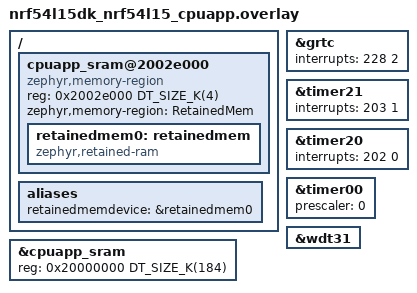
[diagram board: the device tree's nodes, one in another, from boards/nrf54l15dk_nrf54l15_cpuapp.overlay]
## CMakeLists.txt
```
# SPDX-License-Identifier: Apache-2.0

cmake_minimum_required(VERSION 3.20.0)

find_package(Zephyr REQUIRED HINTS $ENV{ZEPHYR_BASE})
project(nrf_grtc_timer)

target_sources(app PRIVATE 
    src/main.c
    src/utc_time.c
    src/retained.c
)
```

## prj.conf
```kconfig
# Disable ZTEST framework
# CONFIG_ZTEST is not set

# GRTC Timer support
CONFIG_NRF_GRTC_TIMER=y
CONFIG_COUNTER=y

# Logging
CONFIG_LOG=y
CONFIG_LOG_PRINTK=y

# System reboot support
CONFIG_REBOOT=y

# Retained memory support for software reset persistence
CONFIG_RETAINED_MEM=y
CONFIG_CRC=y

CONFIG_LOG_MODE_IMMEDIATE=y
CONFIG_WATCHDOG=y
CONFIG_WDT_DISABLE_AT_BOOT=n
```

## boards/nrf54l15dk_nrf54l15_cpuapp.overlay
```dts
/* SPDX-License-Identifier: Apache-2.0 */

&grtc {
	interrupts = <228 2>;
};

test_timer: &timer21 {
	status = "okay";
	interrupts = <203 1>;
};

&timer20 {
	status = "okay";
	interrupts = <202 0>;
};

&timer00 {
	status = "okay";
	prescaler = <0>;
};

&wdt31 {
	status = "okay";
};

/ {
	cpuapp_sram@2002e000 {
		compatible = "zephyr,memory-region", "mmio-sram";
		reg = <0x2002e000 DT_SIZE_K(4)>;
		zephyr,memory-region = "RetainedMem";
		status = "okay";

		retainedmem0: retainedmem {
			compatible = "zephyr,retained-ram";
			status = "okay";
		};
	};

	aliases {
		retainedmemdevice = &retainedmem0;
	};
};

&cpuapp_sram {
	/* Shrink SRAM size to avoid overlap with retained memory region */
	reg = <0x20000000 DT_SIZE_K(184)>;
	ranges = <0x0 0x20000000 0x2e000>;
};
```

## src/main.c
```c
/*
 * Copyright (c) 2024 Nordic Semiconductor ASA
 *
 * SPDX-License-Identifier: Apache-2.0
 * 
 * GRTC RAM Retention Demo
 * Demonstrates that nRF54L15 GRTC automatically persists through software reset
 */

#include <zephyr/kernel.h>
#include <zephyr/logging/log.h>
#include <zephyr/sys/reboot.h>
#include <zephyr/drivers/timer/nrf_grtc_timer.h>
#include "retained.h"
#include <zephyr/drivers/watchdog.h>
#include <zephyr/device.h>
#include <stdbool.h>

LOG_MODULE_REGISTER(utc_time_demo, LOG_LEVEL_INF);

// #define WDT_TEST 0

#define MAX_REBOOTS 3  // Maximum number of automatic resets
#define WDT_FEED_TRIES 5
#define WDT_ALLOW_CALLBACK 0

#ifndef WDT_MAX_WINDOW
#define WDT_MAX_WINDOW  1000U
#endif

#ifndef WDT_MIN_WINDOW
#define WDT_MIN_WINDOW  0U
#endif

#ifndef WDG_FEED_INTERVAL
#define WDG_FEED_INTERVAL 50U
#endif

#ifndef WDT_OPT
#define WDT_OPT WDT_OPT_PAUSE_HALTED_BY_DBG
#endif
int wdt_channel_id;
const struct device *const wdt = DEVICE_DT_GET(DT_ALIAS(watchdog0));

int watch_dog(void)
{
	int err;


	LOG_INF("Watchdog sample application\n");

	if (!device_is_ready(wdt)) {
		LOG_INF("%s: device not ready.\n", wdt->name);
		return 0;
	}

	struct wdt_timeout_cfg wdt_config = {
		/* Reset SoC when watchdog timer expires. */
		.flags = WDT_FLAG_RESET_SOC,

		/* Expire watchdog after max window */
		.window.min = WDT_MIN_WINDOW,
		.window.max = WDT_MAX_WINDOW,
	};

#if WDT_ALLOW_CALLBACK
	/* Set up watchdog callback. */
	wdt_config.callback = wdt_callback;

	LOG_INF("Attempting to test pre-reset callback\n");
#else /* WDT_ALLOW_CALLBACK */
	LOG_INF("Callback in RESET_SOC disabled for this platform\n");
#endif /* WDT_ALLOW_CALLBACK */

	wdt_channel_id = wdt_install_timeout(wdt, &wdt_config);
	if (wdt_channel_id == -ENOTSUP) {
		/* IWDG driver for STM32 doesn't support callback */
		LOG_INF("Callback support rejected, continuing anyway\n");
		wdt_config.callback = NULL;
		wdt_channel_id = wdt_install_timeout(wdt, &wdt_config);
	}
	if (wdt_channel_id < 0) {
		LOG_INF("Watchdog install error\n");
		return 0;
	}

	err = wdt_setup(wdt, WDT_OPT);
	if (err < 0) {
		LOG_INF("Watchdog setup error\n");
		return 0;
	}

#if WDT_MIN_WINDOW != 0
	/* Wait opening window. */
	k_msleep(WDT_MIN_WINDOW);
#endif

	return 0;
}

// Work queue for triggering software reset
static void reboot_work_handler(struct k_work *work);
static K_WORK_DELAYABLE_DEFINE(reboot_work, reboot_work_handler);

static void reboot_work_handler(struct k_work *work)
{
	LOG_WRN("\n========================================");
	LOG_WRN("=== INITIATING SOFTWARE RESET #%u ===", retained.boots + 1);
	LOG_WRN("========================================");
	
	// Record GRTC state before reset
	uint64_t grtc_before = z_nrf_grtc_timer_read();
	
	LOG_WRN("BEFORE RESET:");
	LOG_WRN("  GRTC counter: %llu us (%.3f sec)", grtc_before, (double)grtc_before / 1000000.0);
	
	LOG_WRN("\n>>> Performing software reset NOW...");
	LOG_WRN(">>> GRTC should continue counting from %llu us", grtc_before);
	
	// Update retained memory - increment boots counter
	retained.boots++;
	retained_update();
	LOG_WRN(">>> Saved retained data to RAM:");
	LOG_WRN("    boots=%u, off_count=%u, uptime_sum=%llu", 
	        retained.boots, retained.off_count, retained.uptime_sum);
	
	k_msleep(100); // Allow time for log output
	
	// Execute software reset
	sys_reboot(SYS_REBOOT_COLD);	
}

int main(void)
{
	LOG_INF("GRTC Retention Test Starting...");
	LOG_INF("========================================");
	
	// Initialize retained memory
	bool retained_ok = retained_validate();
	LOG_INF("Retained RAM: %s", retained_ok ? "VALID" : "INVALID (first boot)");
	if (retained_ok) {
		LOG_INF("=== Retained Data ===");
		LOG_INF("  boots:         %u", retained.boots);
		LOG_INF("  off_count:     %u", retained.off_count);
		LOG_INF("  uptime_latest: %llu ticks", retained.uptime_latest);
		LOG_INF("  uptime_sum:    %llu ticks (%.3f sec)", 
		        retained.uptime_sum,
		        (double)retained.uptime_sum * 1000.0 / CONFIG_SYS_CLOCK_TICKS_PER_SEC / 1000.0);
		LOG_INF("  crc:           0x%08x", retained.crc);
	}
	
	// Check GRTC current state (post-reset verification)
	uint64_t grtc_raw = z_nrf_grtc_timer_read();
	
	LOG_INF("GRTC raw counter: %llu us (%.3f seconds)", grtc_raw, (double)grtc_raw / 1000000.0);
	LOG_WRN("Current boot count: %u", retained.boots);

#ifndef WDT_TEST	
	// Check if recovering from software reset
	if (grtc_raw > 1000000ULL) {
		LOG_WRN("========================================");
		LOG_WRN(">>> SUCCESS: GRTC RETENTION WORKING! <<<");
		LOG_WRN("========================================");
		LOG_WRN("Counter value: %llu us = %.3f seconds", grtc_raw, (double)grtc_raw / 1000000.0);
		LOG_WRN("This proves GRTC has been running continuously through software reset!");
		
		// Increment off_count (reset counter)
		retained.off_count++;
	} else {
		LOG_INF(">>> GRTC appears to be freshly started (first boot or hard reset)");
		LOG_INF(">>> Counter < 1 second indicates cold boot");
	}
	
	LOG_INF("Boot count: %u (max reboots: %u)", retained.boots, MAX_REBOOTS);
	LOG_INF("========================================");
	
	// Automatically trigger software reset (to verify retention)
	if (retained.boots < MAX_REBOOTS) {
		LOG_WRN("\n=== AUTO REBOOT TEST ===");
		LOG_WRN("Will trigger software reset in 10 seconds...");
		LOG_WRN("This is to verify GRTC retention across resets");
		LOG_WRN("Current boot count: %u / %u", retained.boots, MAX_REBOOTS);
		
		// Delay 10 seconds before triggering reset
		k_work_schedule(&reboot_work, K_SECONDS(10));
		
		// Countdown display
		for (int i = 10; i > 0; i--) {
			LOG_WRN(">>> Software reset in %d seconds...", i);
			k_sleep(K_SECONDS(1));
		}
	} else {
		LOG_INF("\n=== REBOOT TEST COMPLETE ===");
		LOG_INF(">>> Maximum reboot count (%u) reached", MAX_REBOOTS);
		LOG_INF("========================================");
		LOG_INF(">>> GRTC RETENTION VALIDATED! <<<");
		LOG_INF("========================================");
		LOG_INF("The GRTC counter has persisted through %u software resets", MAX_REBOOTS);
		LOG_INF("Current GRTC value: %llu us (%.3f seconds)", 
		        z_nrf_grtc_timer_read(), 
		        (double)z_nrf_grtc_timer_read() / 1000000.0);
	}
#else
	watch_dog();
#endif		
#ifndef WDT_TEST
	// Keep program running, continuously display GRTC counter
	while (1) {

	k_sleep(K_SECONDS(1));				

	/* Waiting for the SoC reset. */
	LOG_INF("Waiting for reset...\n");		
		k_sleep(K_SECONDS(10));
		uint64_t grtc_current = z_nrf_grtc_timer_read();
		
		// Update retained memory to accumulate uptime
		retained_update();
		
		LOG_INF("=== Status ===");
		LOG_INF("GRTC: %llu us (%.3f sec)", 
		        grtc_current,
		        (double)grtc_current / 1000000.0);
		LOG_INF("Retained: boots=%u, off_count=%u, uptime_sum=%llu ticks (%.3f sec)",
		        retained.boots,
		        retained.off_count,
		        retained.uptime_sum,
		        (double)retained.uptime_sum * 1000.0 / CONFIG_SYS_CLOCK_TICKS_PER_SEC / 1000.0);
	}
#else
	/* Feeding watchdog. */

	LOG_INF("Feeding watchdog %d times\n", WDT_FEED_TRIES);

	for (int i = 0; i < WDT_FEED_TRIES; ++i) {
		LOG_INF("Feeding watchdog...\n");
		wdt_feed(wdt, wdt_channel_id);
		k_sleep(K_MSEC(WDG_FEED_INTERVAL));
	}
#endif	
	return 0;
}
```

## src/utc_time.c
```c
/*
 * UTC Time Management using GRTC Timer
 * Copyright (c) 2025
 * 
 * NOTE: On nRF54L15/nRF54H20, GRTC (Global Real-Time Counter) automatically 
 * persists through software reset when CONFIG_NRF_GRTC_TIMER=y is enabled.
 * No manual KEEPRUNNING register configuration is needed.
 */

#include <zephyr/kernel.h>
#include <zephyr/drivers/timer/nrf_grtc_timer.h>
#include <zephyr/logging/log.h>
#include "utc_time.h"

LOG_MODULE_REGISTER(utc_time, LOG_LEVEL_INF);

/* UTC time offset (microseconds) */
static int64_t utc_offset = 0;
static bool calibrated = false;

/**
 * @brief Calibrate UTC time with external time source
 * 
 * @param utc_timestamp_us UTC timestamp in microseconds
 */
void utc_time_calibrate(uint64_t utc_timestamp_us)
{
	uint64_t grtc_time = z_nrf_grtc_timer_read();
	utc_offset = (int64_t)utc_timestamp_us - (int64_t)grtc_time;
	calibrated = true;
	
	LOG_INF("UTC time calibrated");
	LOG_INF("  GRTC time: %llu us", grtc_time);
	LOG_INF("  UTC time:  %llu us", utc_timestamp_us);
	LOG_INF("  Offset:    %lld us", utc_offset);
}

/**
 * @brief Calibrate UTC time with Unix timestamp (seconds since 1970-01-01)
 * 
 * @param unix_timestamp Unix timestamp in seconds
 */
void utc_time_calibrate_unix(uint64_t unix_timestamp)
{
	uint64_t utc_us = unix_timestamp * 1000000ULL;
	utc_time_calibrate(utc_us);
}

/**
 * @brief Check if UTC time is calibrated
 * 
 * @return true if calibrated, false otherwise
 */
bool utc_time_is_calibrated(void)
{
	return calibrated;
}

/**
 * @brief Get current UTC timestamp in microseconds
 * 
 * @return UTC timestamp in microseconds, or raw GRTC if not calibrated
 */
uint64_t utc_time_get_us(void)
{
	uint64_t grtc_time = z_nrf_grtc_timer_read();
	
	if (!calibrated) {
		LOG_WRN("UTC time not calibrated, returning raw GRTC time");
		return grtc_time;
	}
	
	return grtc_time + utc_offset;
}

/**
 * @brief Get current UTC timestamp in milliseconds
 * 
 * @return UTC timestamp in milliseconds
 */
uint64_t utc_time_get_ms(void)
{
	return utc_time_get_us() / 1000ULL;
}

/**
 * @brief Get current UTC timestamp in seconds
 * 
 * @return UTC timestamp in seconds (Unix timestamp)
 */
uint64_t utc_time_get_sec(void)
{
	return utc_time_get_us() / 1000000ULL;
}

/**
 * @brief Get UTC time as struct
 * 
 * @param time Pointer to utc_time_t structure to fill
 */
void utc_time_get(utc_time_t *time)
{
	if (time == NULL) {
		return;
	}
	
	uint64_t us = utc_time_get_us();
	
	time->microseconds = us;
	time->milliseconds = us / 1000ULL;
	time->seconds = us / 1000000ULL;
	time->calibrated = calibrated;
}

/**
 * @brief Print current UTC time
 */
void utc_time_print(void)
{
	utc_time_t time;
	utc_time_get(&time);
	
	if (time.calibrated) {
		LOG_INF("UTC Time: %llu sec (%llu ms, %llu us)", 
		        time.seconds, time.milliseconds, time.microseconds);
	} else {
		LOG_INF("GRTC Time (not calibrated): %llu us", time.microseconds);
	}
}

/**
 * @brief Get time difference in microseconds
 * 
 * @param time1 First timestamp (microseconds)
 * @param time2 Second timestamp (microseconds)
 * @return Time difference in microseconds (time2 - time1)
 */
int64_t utc_time_diff_us(uint64_t time1, uint64_t time2)
{
	return (int64_t)time2 - (int64_t)time1;
}

/**
 * @brief Convert microseconds to human-readable format
 * 
 * @param us Microseconds
 * @param buffer Output buffer
 * @param size Buffer size
 * @return Number of characters written
 */
int utc_time_format_us(uint64_t us, char *buffer, size_t size)
{
	uint64_t sec = us / 1000000ULL;
	uint64_t ms = (us / 1000ULL) % 1000ULL;
	uint64_t remaining_us = us % 1000ULL;
	
	return snprintf(buffer, size, "%llu.%03llu.%03llu s", sec, ms, remaining_us);
}

/**
 * @brief Format current UTC time to human-readable string
 * 
 * @param buffer Output buffer
 * @param size Buffer size
 * @return Number of characters written
 */
int utc_time_format(char *buffer, size_t size)
{
	uint64_t us = utc_time_get_us();
	return utc_time_format_us(us, buffer, size);
}
```

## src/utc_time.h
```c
/*
 * UTC Time Management using GRTC Timer - Header File
 * 
 * NOTE: On nRF54L15/nRF54H20, GRTC automatically persists through 
 * software reset (CONFIG_NRF_GRTC_TIMER=y). No manual retention
 * configuration is needed.
 */

#ifndef UTC_TIME_H
#define UTC_TIME_H

#include <zephyr/types.h>
#include <stdbool.h>

/**
 * @brief UTC time structure
 */
typedef struct {
	uint64_t microseconds;  /**< Time in microseconds */
	uint64_t milliseconds;  /**< Time in milliseconds */
	uint64_t seconds;       /**< Time in seconds (Unix timestamp) */
	bool calibrated;        /**< Whether time is calibrated */
} utc_time_t;

/**
 * @brief Calibrate UTC time with external time source
 * 
 * @param utc_timestamp_us UTC timestamp in microseconds
 */
void utc_time_calibrate(uint64_t utc_timestamp_us);

/**
 * @brief Calibrate UTC time with Unix timestamp (seconds since 1970-01-01)
 * 
 * @param unix_timestamp Unix timestamp in seconds
 */
void utc_time_calibrate_unix(uint64_t unix_timestamp);

/**
 * @brief Check if UTC time is calibrated
 * 
 * @return true if calibrated, false otherwise
 */
bool utc_time_is_calibrated(void);

/**
 * @brief Get current UTC timestamp in microseconds
 * 
 * @return UTC timestamp in microseconds, or raw GRTC if not calibrated
 */
uint64_t utc_time_get_us(void);

/**
 * @brief Get current UTC timestamp in milliseconds
 * 
 * @return UTC timestamp in milliseconds
 */
uint64_t utc_time_get_ms(void);

/**
 * @brief Get current UTC timestamp in seconds
 * 
 * @return UTC timestamp in seconds (Unix timestamp)
 */
uint64_t utc_time_get_sec(void);

/**
 * @brief Get UTC time as struct
 * 
 * @param time Pointer to utc_time_t structure to fill
 */
void utc_time_get(utc_time_t *time);

/**
 * @brief Print current UTC time
 */
void utc_time_print(void);

/**
 * @brief Get time difference in microseconds
 * 
 * @param time1 First timestamp (microseconds)
 * @param time2 Second timestamp (microseconds)
 * @return Time difference in microseconds (time2 - time1)
 */
int64_t utc_time_diff_us(uint64_t time1, uint64_t time2);

/**
 * @brief Convert microseconds to human-readable format
 * 
 * @param us Microseconds
 * @param buffer Output buffer
 * @param size Buffer size
 * @return Number of characters written
 */
int utc_time_format_us(uint64_t us, char *buffer, size_t size);

/**
 * @brief Format current UTC time to human-readable string
 * 
 * @param buffer Output buffer
 * @param size Buffer size
 * @return Number of characters written
 */
int utc_time_format(char *buffer, size_t size);

#endif /* UTC_TIME_H */
```

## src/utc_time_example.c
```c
/*
 * UTC Time Example - Demonstrates GRTC-based UTC time management
 */

#include <zephyr/kernel.h>
#include <zephyr/logging/log.h>
#include "utc_time.h"

LOG_MODULE_REGISTER(main, LOG_LEVEL_INF);

int main(void)
{
	LOG_INF("=== UTC Time Management Example ===");
	LOG_INF("Using GRTC Timer for high-precision timekeeping");
	
	/* Wait a bit for system to stabilize */
	k_sleep(K_MSEC(100));
	
	/* Example 1: Use raw GRTC time (not calibrated) */
	LOG_INF("\n--- Example 1: Raw GRTC Time ---");
	utc_time_print();
	
	/* Example 2: Calibrate with Unix timestamp */
	LOG_INF("\n--- Example 2: Calibrate UTC Time ---");
	/* December 11, 2025, 00:00:00 UTC = 1765411200 seconds */
	uint64_t unix_timestamp = 1765411200ULL;
	utc_time_calibrate_unix(unix_timestamp);
	
	/* Example 3: Get UTC time in different formats */
	LOG_INF("\n--- Example 3: Get UTC Time ---");
	uint64_t utc_us = utc_time_get_us();
	uint64_t utc_ms = utc_time_get_ms();
	uint64_t utc_sec = utc_time_get_sec();
	
	LOG_INF("UTC time (microseconds): %llu", utc_us);
	LOG_INF("UTC time (milliseconds): %llu", utc_ms);
	LOG_INF("UTC time (seconds):      %llu", utc_sec);
	
	/* Example 4: Use UTC time structure */
	LOG_INF("\n--- Example 4: UTC Time Structure ---");
	utc_time_t time;
	utc_time_get(&time);
	LOG_INF("Calibrated: %s", time.calibrated ? "Yes" : "No");
	LOG_INF("Seconds:    %llu", time.seconds);
	LOG_INF("Millisec:   %llu", time.milliseconds);
	LOG_INF("Microsec:   %llu", time.microseconds);
	
	/* Example 5: Measure time intervals */
	LOG_INF("\n--- Example 5: Measure Time Intervals ---");
	uint64_t start_time = utc_time_get_us();
	k_sleep(K_MSEC(500)); /* Sleep for 500ms */
	uint64_t end_time = utc_time_get_us();
	
	int64_t diff_us = utc_time_diff_us(start_time, end_time);
	LOG_INF("Time interval: %lld us (%.3f ms)", diff_us, diff_us / 1000.0);
	
	/* Example 6: Format time as string */
	LOG_INF("\n--- Example 6: Format Time ---");
	char time_str[64];
	utc_time_format_us(end_time, time_str, sizeof(time_str));
	LOG_INF("Formatted time: %s", time_str);
	
	/* Example 7: Continuous monitoring */
	LOG_INF("\n--- Example 7: Continuous Monitoring ---");
	LOG_INF("Printing UTC time every second (press Ctrl+C to stop)...\n");
	
	int count = 0;
	while (1) {
		utc_time_print();
		
		/* Also demonstrate precision timing */
		uint64_t now = utc_time_get_us();
		uint64_t ms_part = (now / 1000ULL) % 1000ULL;
		uint64_t us_part = now % 1000ULL;
		LOG_INF("  -> Precision: .%03llu.%03llu", ms_part, us_part);
		
		k_sleep(K_SECONDS(1));
		
		count++;
		if (count >= 10) {
			LOG_INF("\nExample completed after 10 seconds");
			break;
		}
	}
	
	LOG_INF("\n=== UTC Time Example Finished ===");
	
	return 0;
}
```
